# CY8C5267AXI_LP051 register map
File version: 0.1
Registers are 8-bit, read-write, no defined reset value unless marked. A register's access mark holds for its fields unless they carry their own. Offsets are from the block's base; [hi:lo] are bit positions; 'fields as' and 'values as' point back to an identical list.

## MMU4_Addr_2
Base 0x00000000
0x4000647E MMU4_Addr_2_CONTROL_REG

## MMU4_Addr_1
Base 0x00000000
0x4000647B MMU4_Addr_1_CONTROL_REG

## MMU4_Addr_3
Base 0x00000000
0x4000647F MMU4_Addr_3_CONTROL_REG

## AdrLowOut
Base 0x00000000
0x40006471 AdrLowOut_CONTROL_REG

## BankBaseAdr
Base 0x00000000
0x40006476 BankBaseAdr_CONTROL_REG

## IO_Ctrl_Reg
Base 0x00000000
0x40006574 IO_Ctrl_Reg_CONTROL_REG

## AdrMidOut
Base 0x00000000
0x40006473 AdrMidOut_CONTROL_REG

## RTC
Base 0x00000000
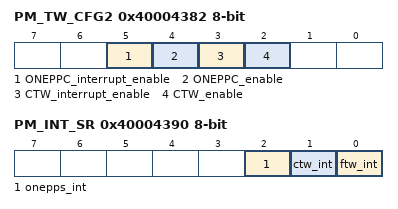
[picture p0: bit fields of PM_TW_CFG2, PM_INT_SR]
0x40004382 PM_TW_CFG2 — Power timers enable and interrupt enable configuration register
  [5] ONEPPC_interrupt_enable — When set and one pulse-per-second is enabled, an interrupt is issued when the pulse occurs
    1=Enabled (The ONEPPC interrupt is issued. Only if ONEPPC is enabled.); 0=Disabled (No ONEPPC interrupt is issued.)
  [4] ONEPPC_enable
    1=Enabled (The ONEPPC is enabled.); 0=Disabled (The ONEPPC is disabled.)
  [3] CTW_interrupt_enable — An interrupt issue when the CTW reaches the selected interval
    1=Enabled (The CTW interrupt is issued. Only if CTW is enabled.); 0=Disabled (No CTW interrupt is issued.)
  [2] CTW_enable
    1=Enabled (The CTW is enabled.); 0=Disabled (The CTW is disabled.)
0x40004390 PM_INT_SR — Power Manager Interrupt Status Register
  [2] onepps_int — When set, a onepps event has occured.
  [1] ctw_int — When set, a limited active ready event has occured
  [0] ftw_int — When set, a fast timewheel event has occured

## Z80_Data_In
Base 0x00000000
0x4000657A Z80_Data_In_CONTROL_REG

## Z80_Data_Out
Base 0x00000000
0x4000646E Z80_Data_Out_STATUS_REG
0x4000648E Z80_Data_Out_MASK_REG
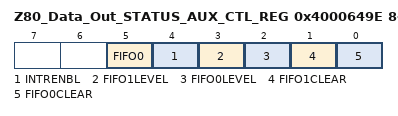
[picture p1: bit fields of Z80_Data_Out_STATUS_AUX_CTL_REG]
0x4000649E Z80_Data_Out_STATUS_AUX_CTL_REG
  [5] FIFO0 — FIFO0 clear
    1=ENABLED (Enable counter); 0=DISABLED (Disable counter)
  [4] INTRENBL — Enables or disables the Interrupt
    1=ENABLED (Interrupt enabled); 0=DISABLED (Interrupt disabled)
  [3] FIFO1LEVEL — FIFO level
    1=ENABLED (FIFO LVL: input mode: FIFO at least 1/2 empty; output mode: FIFO at least 1/2 full); 0=DISABLED (FIFO LVL: input mode: FIFO not full; output mode: FIFO not empty)
  [2] FIFO0LEVEL — FIFO level
    values as FIFO1LEVEL
  [1] FIFO1CLEAR — FIFO clear
    1=ENABLED (Clear FIFO state); 0=DISABLED (Normal FIFO operation)
  [0] FIFO0CLEAR — FIFO clear
    values as FIFO1CLEAR

## AdrLowIn
Base 0x00000000
0x40006461 AdrLowIn_STATUS_REG
0x40006481 AdrLowIn_MASK_REG
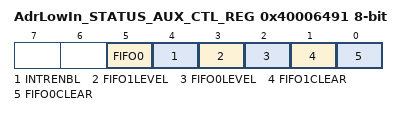
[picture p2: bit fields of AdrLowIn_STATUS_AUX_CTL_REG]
0x40006491 AdrLowIn_STATUS_AUX_CTL_REG
  [5] FIFO0 — FIFO0 clear
    1=ENABLED (Enable counter); 0=DISABLED (Disable counter)
  [4] INTRENBL — Enables or disables the Interrupt
    1=ENABLED (Interrupt enabled); 0=DISABLED (Interrupt disabled)
  [3] FIFO1LEVEL — FIFO level
    1=ENABLED (FIFO LVL: input mode: FIFO at least 1/2 empty; output mode: FIFO at least 1/2 full); 0=DISABLED (FIFO LVL: input mode: FIFO not full; output mode: FIFO not empty)
  [2] FIFO0LEVEL — FIFO level
    values as FIFO1LEVEL
  [1] FIFO1CLEAR — FIFO clear
    1=ENABLED (Clear FIFO state); 0=DISABLED (Normal FIFO operation)
  [0] FIFO0CLEAR — FIFO clear
    values as FIFO1CLEAR

## IO_Stat_Reg
Base 0x00000000
0x40006564 IO_Stat_Reg_STATUS_REG
0x40006584 IO_Stat_Reg_MASK_REG
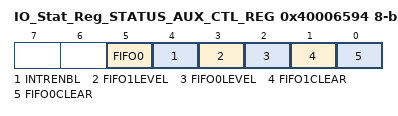
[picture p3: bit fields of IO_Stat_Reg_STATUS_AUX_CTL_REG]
0x40006594 IO_Stat_Reg_STATUS_AUX_CTL_REG
  [5] FIFO0 — FIFO0 clear
    1=ENABLED (Enable counter); 0=DISABLED (Disable counter)
  [4] INTRENBL — Enables or disables the Interrupt
    1=ENABLED (Interrupt enabled); 0=DISABLED (Interrupt disabled)
  [3] FIFO1LEVEL — FIFO level
    1=ENABLED (FIFO LVL: input mode: FIFO at least 1/2 empty; output mode: FIFO at least 1/2 full); 0=DISABLED (FIFO LVL: input mode: FIFO not full; output mode: FIFO not empty)
  [2] FIFO0LEVEL — FIFO level
    values as FIFO1LEVEL
  [1] FIFO1CLEAR — FIFO clear
    1=ENABLED (Clear FIFO state); 0=DISABLED (Normal FIFO operation)
  [0] FIFO0CLEAR — FIFO clear
    values as FIFO1CLEAR

## BankMask
Base 0x00000000
0x40006477 BankMask_CONTROL_REG

## SPI_SS_Out
Base 0x00000000
0x40006576 SPI_SS_Out_CONTROL_REG
